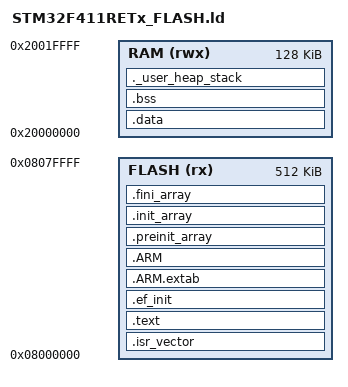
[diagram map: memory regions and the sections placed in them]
/*
 * STM32F411RETx_FLASH.ld — STM32F411RE 链接脚本
 * Flash: 512KB @ 0x08000000   RAM: 128KB @ 0x20000000
 *
 * 额外定义 .ef_init 段：配合 driver/device/ef_init.h 的 EF_INIT_EXPORT
 * 宏实现模块自动注册（新增模块只需要一个宏，不需要手改 main）。
 * 段内按 "1_board" < "2_driver" < "3_service" < "4_app" 字典序排列，
 * ef_init_run_all() 按此顺序遍历执行，保证初始化次序正确。
 */

ENTRY(Reset_Handler)

MEMORY
{
    FLASH (rx)  : ORIGIN = 0x08000000, LENGTH = 512K
    RAM   (rwx) : ORIGIN = 0x20000000, LENGTH = 128K
}

_estack = ORIGIN(RAM) + LENGTH(RAM);

SECTIONS
{
    .isr_vector :
    {
        . = ALIGN(4);
        KEEP(*(.isr_vector))
        . = ALIGN(4);
    } >FLASH

    .text :
    {
        . = ALIGN(4);
        *(.text)
        *(.text*)
        *(.rodata)
        *(.rodata*)
        KEEP(*(.init))
        KEEP(*(.fini))
        . = ALIGN(4);
    } >FLASH

    /* 模块自动注册表：按名称字典序排列 4 个初始化阶段 */
    .ef_init :
    {
        . = ALIGN(4);
        __ef_init_start = .;
        KEEP(*(SORT(.ef_init.*)))
        __ef_init_end = .;
        . = ALIGN(4);
    } >FLASH

    .ARM.extab : { *(.ARM.extab* .gnu.linkonce.armextab.*) } >FLASH
    .ARM : { __exidx_start = .; *(.ARM.exidx*) __exidx_end = .; } >FLASH

    .preinit_array :
    {
        PROVIDE_HIDDEN(__preinit_array_start = .);
        KEEP(*(.preinit_array*))
        PROVIDE_HIDDEN(__preinit_array_end = .);
    } >FLASH

    .init_array :
    {
        PROVIDE_HIDDEN(__init_array_start = .);
        KEEP(*(SORT(.init_array.*)))
        KEEP(*(.init_array*))
        PROVIDE_HIDDEN(__init_array_end = .);
    } >FLASH

    .fini_array :
    {
        PROVIDE_HIDDEN(__fini_array_start = .);
        KEEP(*(SORT(.fini_array.*)))
        KEEP(*(.fini_array*))
        PROVIDE_HIDDEN(__fini_array_end = .);
    } >FLASH

    /* 所有只读段排完后，再放置 .data 的 LMA，避免与 libc .init 重叠 */
    _etext = .;

    .data : AT (_etext)
    {
        . = ALIGN(4);
        _sdata = .;
        *(.data)
        *(.data*)
        . = ALIGN(4);
        _edata = .;
    } >RAM

    _sidata = LOADADDR(.data);

    .bss :
    {
        . = ALIGN(4);
        _sbss = .;
        *(.bss)
        *(.bss*)
        *(COMMON)
        . = ALIGN(4);
        _ebss = .;
    } >RAM

    ._user_heap_stack :
    {
        . = ALIGN(8);
        PROVIDE(end = .);
        . = . + 0x400; /* 最小堆保留，本脚手架业务层禁止 malloc，仅第三方库可能需要 */
        . = ALIGN(8);
    } >RAM

    /DISCARD/ :
    {
        libc.a ( * )
        libm.a ( * )
        libgcc.a ( * )
    }

    .ARM.attributes 0 : { *(.ARM.attributes) }
}
